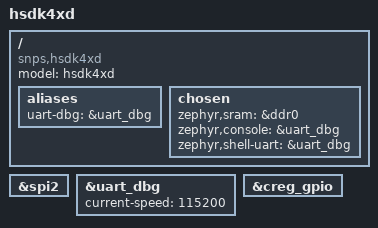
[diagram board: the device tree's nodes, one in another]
/*
 * Copyright (c) 2023, Synopsys, Inc. All rights reserved.
 *
 * SPDX-License-Identifier: Apache-2.0
 */

/dts-v1/;

#include <synopsys/arc_hs4xd.dtsi>

/ {
	model = "hsdk4xd";
	compatible = "snps,hsdk4xd";

	aliases {
		uart-dbg = &uart_dbg;
	};

	chosen {
		zephyr,sram = &ddr0;
		zephyr,console = &uart_dbg;
		zephyr,shell-uart = &uart_dbg;
	};
};

arduino_spi: &spi2 {};

&uart_dbg {
	status = "okay";
	current-speed = <115200>;
};

&creg_gpio {
	status = "okay";
};
